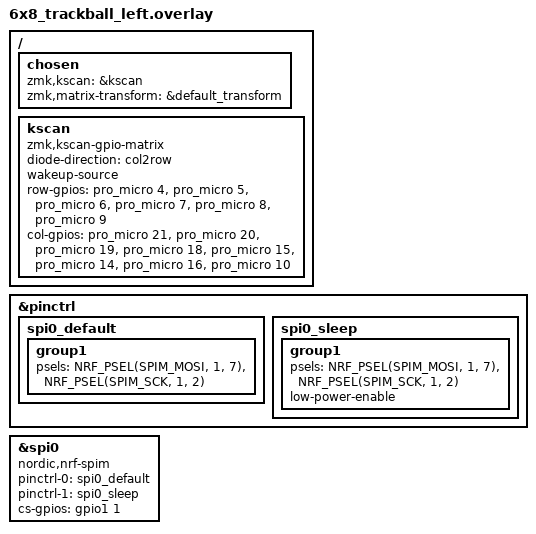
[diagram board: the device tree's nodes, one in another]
#include "6x8_trackball.dts"
/ {
    chosen {
        zmk,kscan = &kscan;
        zmk,matrix-transform = &default_transform;
    };

    kscan: kscan {
        compatible = "zmk,kscan-gpio-matrix";
        diode-direction = "col2row";
        wakeup-source;

        row-gpios
            = <&pro_micro 4 (GPIO_ACTIVE_HIGH | GPIO_PULL_DOWN)>
            , <&pro_micro 5 (GPIO_ACTIVE_HIGH | GPIO_PULL_DOWN)>
            , <&pro_micro 6 (GPIO_ACTIVE_HIGH | GPIO_PULL_DOWN)>
            , <&pro_micro 7 (GPIO_ACTIVE_HIGH | GPIO_PULL_DOWN)>
            , <&pro_micro 8 (GPIO_ACTIVE_HIGH | GPIO_PULL_DOWN)>
            , <&pro_micro 9 (GPIO_ACTIVE_HIGH | GPIO_PULL_DOWN)>
            ;

        col-gpios
            = <&pro_micro 21 GPIO_ACTIVE_HIGH>
            , <&pro_micro 20 GPIO_ACTIVE_HIGH>
            , <&pro_micro 19 GPIO_ACTIVE_HIGH>
            , <&pro_micro 18 GPIO_ACTIVE_HIGH>
            , <&pro_micro 15 GPIO_ACTIVE_HIGH>
            , <&pro_micro 14 GPIO_ACTIVE_HIGH>
            , <&pro_micro 16 GPIO_ACTIVE_HIGH>
            , <&pro_micro 10 GPIO_ACTIVE_HIGH>
            ;
    };
};

&pinctrl {
    spi0_default: spi0_default {
        group1 {
            psels = <NRF_PSEL(SPIM_MOSI, 1, 7)>,    // Set P1.07 as MOSI
                    <NRF_PSEL(SPIM_SCK, 1, 2)>;     // Set P1.02 as SCK
        };
    };
    
    spi0_sleep: spi0_sleep {
        group1 {
            psels = <NRF_PSEL(SPIM_MOSI, 1, 7)>,    // Set P1.07 as MOSI
                    <NRF_PSEL(SPIM_SCK, 1, 2)>;     // Set P1.02 as SCK
            low-power-enable;
        };
    };
};

nice_view_spi: &spi0 {
    compatible = "nordic,nrf-spim";
    pinctrl-0 = <&spi0_default>;
    pinctrl-1 = <&spi0_sleep>;
    pinctrl-names = "default", "sleep";
    cs-gpios = <&gpio1 1 GPIO_ACTIVE_HIGH>;
};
